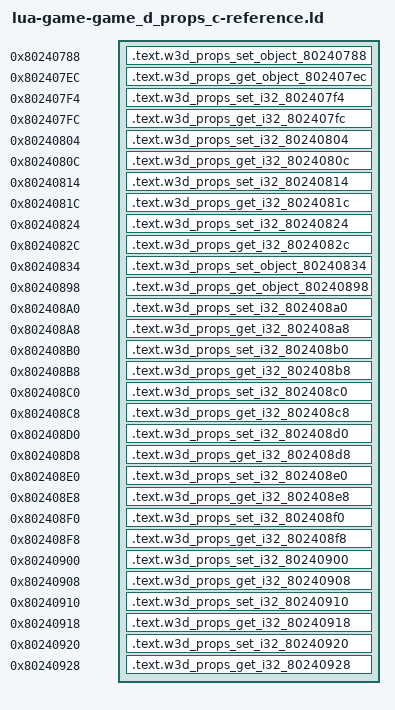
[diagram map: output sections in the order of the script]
/* Generated reference-only placements. All bodies are source-built. */
OUTPUT_FORMAT("elf32-powerpc")
OUTPUT_ARCH(powerpc)
ENTRY(w3d_props_set_object_80240788)
_SDA_BASE_ = 0x804b2540;
_SDA2_BASE_ = 0x804c2540;
SECTIONS {
  .text.w3d_props_set_object_80240788 0x80240788 : { *(.text.w3d_props_set_object_80240788) }
  .text.w3d_props_get_object_802407ec 0x802407ec : { *(.text.w3d_props_get_object_802407ec) }
  .text.w3d_props_set_i32_802407f4 0x802407f4 : { *(.text.w3d_props_set_i32_802407f4) }
  .text.w3d_props_get_i32_802407fc 0x802407fc : { *(.text.w3d_props_get_i32_802407fc) }
  .text.w3d_props_set_i32_80240804 0x80240804 : { *(.text.w3d_props_set_i32_80240804) }
  .text.w3d_props_get_i32_8024080c 0x8024080c : { *(.text.w3d_props_get_i32_8024080c) }
  .text.w3d_props_set_i32_80240814 0x80240814 : { *(.text.w3d_props_set_i32_80240814) }
  .text.w3d_props_get_i32_8024081c 0x8024081c : { *(.text.w3d_props_get_i32_8024081c) }
  .text.w3d_props_set_i32_80240824 0x80240824 : { *(.text.w3d_props_set_i32_80240824) }
  .text.w3d_props_get_i32_8024082c 0x8024082c : { *(.text.w3d_props_get_i32_8024082c) }
  .text.w3d_props_set_object_80240834 0x80240834 : { *(.text.w3d_props_set_object_80240834) }
  .text.w3d_props_get_object_80240898 0x80240898 : { *(.text.w3d_props_get_object_80240898) }
  .text.w3d_props_set_i32_802408a0 0x802408a0 : { *(.text.w3d_props_set_i32_802408a0) }
  .text.w3d_props_get_i32_802408a8 0x802408a8 : { *(.text.w3d_props_get_i32_802408a8) }
  .text.w3d_props_set_i32_802408b0 0x802408b0 : { *(.text.w3d_props_set_i32_802408b0) }
  .text.w3d_props_get_i32_802408b8 0x802408b8 : { *(.text.w3d_props_get_i32_802408b8) }
  .text.w3d_props_set_i32_802408c0 0x802408c0 : { *(.text.w3d_props_set_i32_802408c0) }
  .text.w3d_props_get_i32_802408c8 0x802408c8 : { *(.text.w3d_props_get_i32_802408c8) }
  .text.w3d_props_set_i32_802408d0 0x802408d0 : { *(.text.w3d_props_set_i32_802408d0) }
  .text.w3d_props_get_i32_802408d8 0x802408d8 : { *(.text.w3d_props_get_i32_802408d8) }
  .text.w3d_props_set_i32_802408e0 0x802408e0 : { *(.text.w3d_props_set_i32_802408e0) }
  .text.w3d_props_get_i32_802408e8 0x802408e8 : { *(.text.w3d_props_get_i32_802408e8) }
  .text.w3d_props_set_i32_802408f0 0x802408f0 : { *(.text.w3d_props_set_i32_802408f0) }
  .text.w3d_props_get_i32_802408f8 0x802408f8 : { *(.text.w3d_props_get_i32_802408f8) }
  .text.w3d_props_set_i32_80240900 0x80240900 : { *(.text.w3d_props_set_i32_80240900) }
  .text.w3d_props_get_i32_80240908 0x80240908 : { *(.text.w3d_props_get_i32_80240908) }
  .text.w3d_props_set_i32_80240910 0x80240910 : { *(.text.w3d_props_set_i32_80240910) }
  .text.w3d_props_get_i32_80240918 0x80240918 : { *(.text.w3d_props_get_i32_80240918) }
  .text.w3d_props_set_i32_80240920 0x80240920 : { *(.text.w3d_props_set_i32_80240920) }
  .text.w3d_props_get_i32_80240928 0x80240928 : { *(.text.w3d_props_get_i32_80240928) }
  /DISCARD/ : { *(.text*) *(.rodata*) *(.data*) *(.bss*) *(.sdata*) *(.sbss*) *(.comment) }
}
